# GD32A72_A74x register map
File version: 1.0
CPU: CM7 r2p1, little endian, MPU, FPU, DSP, 4 interrupt priority bits
Registers are 32-bit, read-write, reset 0x0 unless marked. A register's access mark holds for its fields unless they carry their own. Offsets are from the block's base; [hi:lo] are bit positions; {n}, {i} and the like mark numbered series; 'fields as' and 'values as' point back to an identical list.

## SRAM
Base 0x49000C00
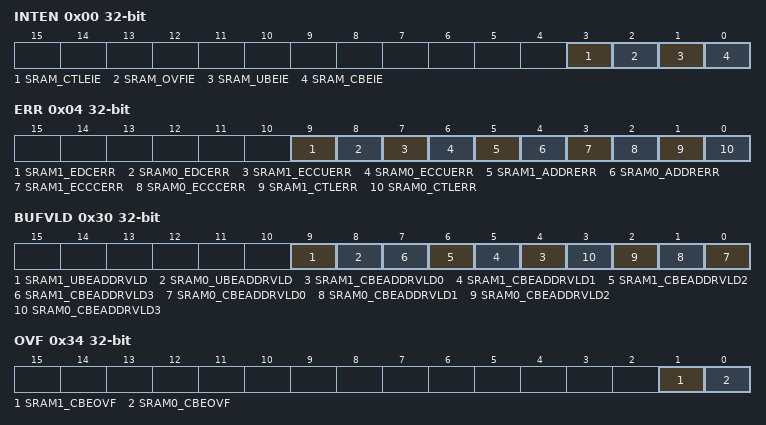
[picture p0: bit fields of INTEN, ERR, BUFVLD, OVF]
0x00 INTEN — SRAM interrupt enable register
  [3] SRAM_CTLEIE — SRAM0/1 controller redundancy check error interrupt enable
  [2] SRAM_OVFIE — SRAM0/1 address buffer overflow interrupt enable
  [1] SRAM_UBEIE — SRAM0/1 uncorrectable bit error interrupt enable
  [0] SRAM_CBEIE — SRAM0/1 correctable bit error interrupt enable
0x04 ERR — SRAM error status register
  [9] SRAM1_EDCERR — SRAM1 EDC after ECC checker error flag
  [8] SRAM0_EDCERR — SRAM0 EDC after ECC checker error flag
  [7] SRAM1_ECCUERR — SRAM1 ECC double bit uncorrectable error flag
  [6] SRAM0_ECCUERR — SRAM0 ECC double bit uncorrectable error flag
  [5] SRAM1_ADDRERR — SRAM1 ECC single bit address error flag
  [4] SRAM0_ADDRERR — SRAM0 ECC single bit address error flag
  [3] SRAM1_ECCCERR — SRAM1 ECC single bit correctable error flag
  [2] SRAM0_ECCCERR — SRAM0 ECC single bit correctable error flag
  [1] SRAM1_CTLERR — SRAM1 controller redundancy check error flag
  [0] SRAM0_CTLERR — SRAM0 controller redundancy check error flag
0x08 CBEADDR0_0 ro reset 0x24000000 — SRAM correctable bit error address 0 for SRAM_0
  [31:0] SRAM_CBEADDR0 — Record the first correctable bit error address
0x0C CBEADDR0_1 ro reset 0x24000000 — SRAM correctable bit error address 0 for SRAM_1
  fields as CBEADDR0_0
0x10 CBEADDR1_0 ro reset 0x24000000 — SRAM correctable bit error address 1 for SRAM_0
  [31:0] SRAM_CBEADDR1 — Record the second correctable bit error address
0x14 CBEADDR1_1 ro reset 0x24000000 — SRAM correctable bit error address 1 for SRAM_1
  fields as CBEADDR1_0
0x18 CBEADDR2_0 ro reset 0x24000000 — SRAM correctable bit error address 2 for SRAM_0
  [31:0] SRAM_CBEADDR2 — Record the third correctable bit error address
0x1C CBEADDR2_1 ro reset 0x24000000 — SRAM correctable bit error address 2 for SRAM_1
  fields as CBEADDR2_0
0x20 CBEADDR3_0 ro reset 0x24000000 — SRAM correctable bit error address 3 for SRAM_0
  [31:0] SRAM_CBEADDR3 — Record the fourth correctable bit error address
0x24 CBEADDR3_1 ro reset 0x24000000 — SRAM correctable bit error address 3 for SRAM_1
  fields as CBEADDR3_0
0x28 UBEADDR_0 ro reset 0x24000000 — SRAM correctable bit error address for SRAM_0
  [31:0] SRAM_UBEADDR — Record the un-correctable bit error address
0x2C UBEADDR_1 ro reset 0x24000000 — SRAM correctable bit error address for SRAM_1
  [31:0] SRAM_UBEADDR — Record the un-correctable bit error address
0x30 BUFVLD — SRAM buffer valid register
  [9] SRAM1_UBEADDRVLD — SRAM1 un-correctable bit error address valid flag
  [8] SRAM0_UBEADDRVLD — SRAM0 un-correctable bit error address valid flag
  [n+4] SRAM1_CBEADDRVLD{n} (n=0..3) — SRAM1 correctable bit error address{n} valid flag
  [n] SRAM0_CBEADDRVLD{n} (n=0..3) — SRAM0 correctable bit error address{n} valid flag
0x34 OVF — SRAM overflow status register
  [1] SRAM1_CBEOVF — SRAM1 correctable bit error address buffer overflow
  [0] SRAM0_CBEOVF — SRAM0 correctable bit error address buffer overflow
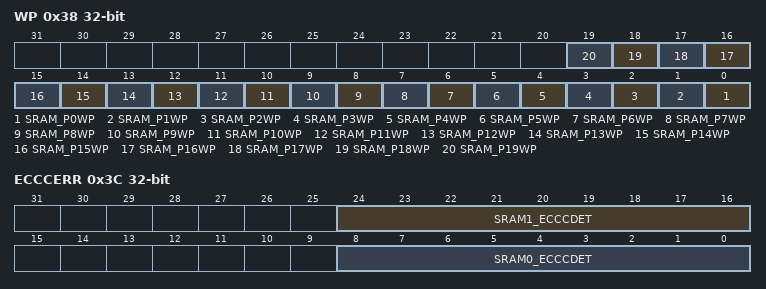
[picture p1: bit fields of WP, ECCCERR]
0x38 WP — SRAM write protection register
  [n] SRAM_P{n}WP (n=0..19) — SRAM page {n} write protection (a page granularity is 16Kbyte)
0x3C ECCCERR access per field — SRAM ECC code error status register
  [24:16] SRAM1_ECCCDET ro — SRAM1 ecc code calculated with check error detected to identify the position on a single-bit inversion
  [8:0] SRAM0_ECCCDET rw — SRAM0 ecc code calculated with check error detected to identify the position on a single-bit inversion

## TIMER5 — Basic timer
Base 0x40016000
Same registers: TIMER6 0x40001400
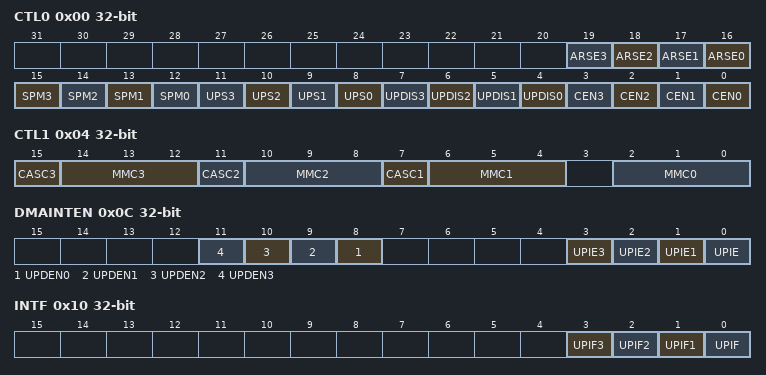
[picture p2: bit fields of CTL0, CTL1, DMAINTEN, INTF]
0x00 CTL0 — Control register 0
  [n+16] ARSE{n} (n=0..3) — Auto-reload shadow enable of channel {n}
  [15] SPM3 — Single pulse mode of channel 3
  [14] SPM2 — Single pulse mode of channel2
  [13] SPM1 — Single pulse mode of channel 1
  [12] SPM0 — Single pulse mode of channel
  [n+8] UPS{n} (n=0..3) — Update source of channel {n}
  [n+4] UPDIS{n} (n=0..3) — Update disable of channel {n}
  [n] CEN{n} (n=0..3) — Counter enable of channel {n}
0x04 CTL1 — Control register 1
  [15] CASC3 — Cascade mode of channel 2 enable
  [4n+2:4n] MMC{n} (n=0..3) — Master mode control of channel {n}
  [11] CASC2 — Cascade mode of channel 2 enable
  [7] CASC1 — Cascade mode of channel 1 enable
0x0C DMAINTEN — Interrupt enable register
  [n+8] UPDEN{n} (n=0..3) — Update DMA request enable of channel {n}
  [3] UPIE3 — Update interrupt enable of channel 3
  [2] UPIE2 — Update interrupt enable of channel 2
  [1] UPIE1 — Update interrupt enable of channel 1
  [0] UPIE — Update interrupt enable of channel 0
0x10 INTF — Interrupt flag register
  [3] UPIF3 — Update interrupt flag of channel 3
  [2] UPIF2 — Update interrupt flag of channel 2
  [1] UPIF1 — Update interrupt flag of channel 1
  [0] UPIF — Update interrupt flag of channel 0
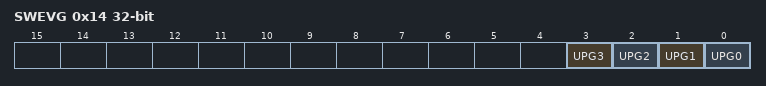
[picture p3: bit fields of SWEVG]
0x14 SWEVG wo — Software event generation register
  [3] UPG3 — Refer to UPG0
  [2] UPG2 — Refer to UPG0
  [1] UPG1 — Refer to UPG0
  [0] UPG0 — This bit can be set by software, and automatically cleared by hardware
{0x18+4i} CNT{i} (i=0..3) — Counter register
  [31:0] CNT{i} — This bit-field indicates the current counter value of channel {i}
{0x28+4i} PSC{i} (i=0..3) — Prescaler register
  [15:0] PSC{i} — Prescaler value of the counter clock of channel {i}
{0x38+4i} CAR{i} (i=0..3) — Counter auto reload register
  [31:0] CARL{i} — Counter auto reload value of channel {i}
0x48 CASCH — Cascade timer high register
  [31:0] CASCH — These bits store the high 32 bits of the 64bit counter in cascade mode
0x4C CASCL — Cascade timer low register
  [31:0] CASL — These bits store the low 32 bits of the 64bit counter in cascade mode

## WWDGT0 — Window watchdog timer
Base 0x40002C00
Same registers: WWDGT1 0x4000DC00
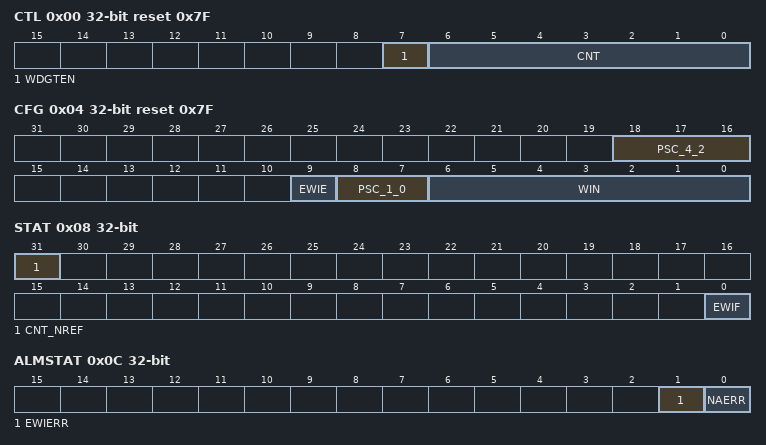
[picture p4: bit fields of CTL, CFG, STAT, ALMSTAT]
0x00 CTL reset 0x7F — Control register
  [7] WDGTEN — Start the Window watchdog timer
  [6:0] CNT — The value of the watchdog timer counter
0x04 CFG reset 0x7F — Configuration register
  [18:16] PSC_4_2 — PSC[4:2],refer to PSC[1:0] description
  [9] EWIE — Early wakeup interrupt enable
  [8:7] PSC_1_0 — Prescaler
  [6:0] WIN — The Window value
0x08 STAT access per field — Status register
  [31] CNT_NREF ro — CNT not refresh flag
  [0] EWIF rw — Early wakeup interrupt flag
0x0C ALMSTAT — ALARM Status register
  [1] EWIERR — Early wakeup interrupt cannot be generated normally error flag
  [0] NAERR — WWDGT cannot be activated error flag
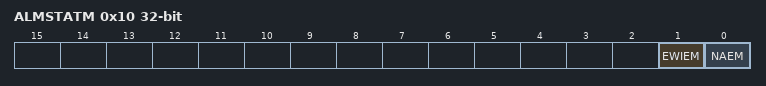
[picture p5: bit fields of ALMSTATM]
0x10 ALMSTATM — ALARM Status Mask register
  [1] EWIEM — EWIERR status mask bit
  [0] NAEM — NAERR status mask bit
